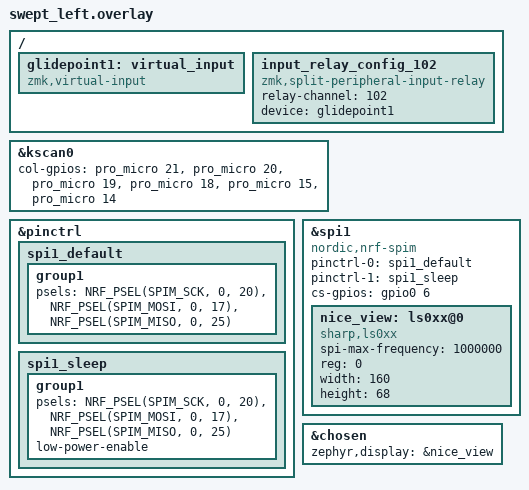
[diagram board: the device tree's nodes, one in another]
/*
 * Copyright (c) 2022 The ZMK Contributors
 *
 * SPDX-License-Identifier: MIT
 */

#include "swept.dtsi"

&kscan0  {
    col-gpios
        = <&pro_micro 21 GPIO_ACTIVE_HIGH>
        , <&pro_micro 20 GPIO_ACTIVE_HIGH>
        , <&pro_micro 19 GPIO_ACTIVE_HIGH>
        , <&pro_micro 18 GPIO_ACTIVE_HIGH>
        , <&pro_micro 15 GPIO_ACTIVE_HIGH>
        , <&pro_micro 14 GPIO_ACTIVE_HIGH>
        ;
};


&pinctrl {
  spi1_default: spi1_default {
    group1 {
      psels = <NRF_PSEL(SPIM_SCK, 0, 20)>,
        <NRF_PSEL(SPIM_MOSI, 0, 17)>,
        <NRF_PSEL(SPIM_MISO, 0, 25)>;
    };
  };
  spi1_sleep: spi1_sleep {
    group1 {
      psels = <NRF_PSEL(SPIM_SCK, 0, 20)>,
        <NRF_PSEL(SPIM_MOSI, 0, 17)>,
        <NRF_PSEL(SPIM_MISO, 0, 25)>;
      low-power-enable;
    };
  };
};

nice_view_spi: &spi1 {
  compatible = "nordic,nrf-spim";
  pinctrl-0 = <&spi1_default>;
  pinctrl-1 = <&spi1_sleep>;
  pinctrl-names = "default", "sleep";
  cs-gpios = <&gpio0 6 GPIO_ACTIVE_HIGH>;

  nice_view: ls0xx@0 {
    compatible = "sharp,ls0xx";
    spi-max-frequency = <1000000>;
    reg = <0>;
    width = <160>;
    height = <68>;
  };
};

&chosen {
  zephyr,display = &nice_view;
};

// nice view bus
&nice_view_spi {
  status = "okay";
};

&nice_view {
  status = "okay";
};

/ {
    /* define virtual input, will be resurrected for emitting input event */
	/* NOTE: set `device = <&glidepoint1>` in `zmk,input-listener` */
	glidepoint1: virtual_input {
		compatible = "zmk,virtual-input";
	};

	/* for central side, define (relay-channel)-to-(virtual-input) mapping */
	input_relay_config_102 {
		compatible = "zmk,split-peripheral-input-relay";
		
		/* channel id, used to filter incoming input event from split peripheral */
		/* NOTE: should matching relay-channel on peripheral overlay */
		relay-channel = <102>;

		/* virtual input device on central, which used to emit input event as an agent device */
		device = <&glidepoint1>;
	};
};

